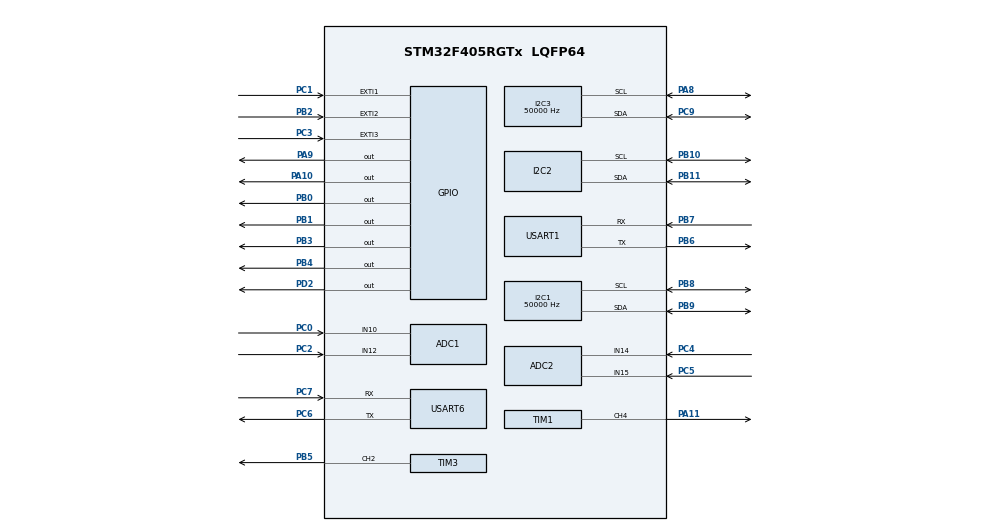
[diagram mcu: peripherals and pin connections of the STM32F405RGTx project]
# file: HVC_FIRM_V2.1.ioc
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ADC1.Channel-0\#ChannelRegularConversion=ADC_CHANNEL_10
ADC1.ClockPrescaler=ADC_CLOCK_SYNC_PCLK_DIV4
ADC1.NbrOfConversionFlag=1
ADC1.Rank-0\#ChannelRegularConversion=1
ADC1.SamplingTime-0\#ChannelRegularConversion=ADC_SAMPLETIME_3CYCLES
ADC1.master=1
ADC2.Channel-0\#ChannelRegularConversion=ADC_CHANNEL_14
ADC2.ClockPrescaler=ADC_CLOCK_SYNC_PCLK_DIV4
ADC2.NbrOfConversionFlag=1
ADC2.Rank-0\#ChannelRegularConversion=1
ADC2.SamplingTime-0\#ChannelRegularConversion=ADC_SAMPLETIME_3CYCLES
I2C1.ClockSpeed=50000
I2C3.ClockSpeed=50000
Mcu.Family=STM32F4
Mcu.Name=STM32F405RGTx
Mcu.Package=LQFP64
NVIC.ADC_IRQn=true\:3\:0\:true\:false\:true\:true\:true\:true
NVIC.EXTI1_IRQn=true\:1\:0\:true\:false\:true\:true\:true\:true
NVIC.EXTI2_IRQn=true\:2\:0\:true\:false\:true\:true\:true\:true
NVIC.EXTI3_IRQn=true\:1\:0\:true\:false\:true\:true\:true\:true
NVIC.PriorityGroup=NVIC_PRIORITYGROUP_4
NVIC.USART1_IRQn=true\:2\:0\:true\:false\:true\:true\:true\:true
NVIC.USART6_IRQn=true\:6\:0\:true\:false\:true\:true\:true\:true
PA10.Signal=GPIO_Output
PA11.Signal=S_TIM1_CH4
PA13.Mode=Serial_Wire
PA13.Signal=SYS_JTMS-SWDIO
PA14.Mode=Serial_Wire
PA14.Signal=SYS_JTCK-SWCLK
PA8.Mode=I2C
PA8.Signal=I2C3_SCL
PA9.Signal=GPIO_Output
PB0.Signal=GPIO_Output
PB1.Signal=GPIO_Output
PB10.Mode=I2C
PB10.Signal=I2C2_SCL
PB11.Mode=I2C
PB11.Signal=I2C2_SDA
PB2.GPIO_ModeDefaultEXTI=GPIO_MODE_IT_FALLING
PB2.Signal=GPXTI2
PB3.Signal=GPIO_Output
PB4.Signal=GPIO_Output
PB5.Signal=S_TIM3_CH2
PB6.Mode=Asynchronous
PB6.Signal=USART1_TX
PB7.GPIO_PuPd=GPIO_PULLUP
PB7.Mode=Asynchronous
PB7.Signal=USART1_RX
PB8.Mode=I2C
PB8.Signal=I2C1_SCL
PB9.Mode=I2C
PB9.Signal=I2C1_SDA
PC0.Signal=ADCx_IN10
PC1.Signal=GPXTI1
PC2.Signal=ADCx_IN12
PC3.Signal=GPXTI3
PC4.Signal=ADCx_IN14
PC5.Signal=ADCx_IN15
PC6.Mode=Asynchronous
PC6.Signal=USART6_TX
PC7.GPIO_PuPd=GPIO_PULLUP
PC7.Mode=Asynchronous
PC7.Signal=USART6_RX
PC9.Mode=I2C
PC9.Signal=I2C3_SDA
PD2.Signal=GPIO_Output
PH0-OSC_IN.Mode=HSE-External-Oscillator
PH0-OSC_IN.Signal=RCC_OSC_IN
PH1-OSC_OUT.Mode=HSE-External-Oscillator
PH1-OSC_OUT.Signal=RCC_OSC_OUT
ProjectManager.HeapSize=0x200
ProjectManager.StackSize=0x400
ProjectManager.TargetToolchain=STM32CubeIDE
RCC.48MHZClocksFreq_Value=36000000
RCC.AHBCLKDivider=RCC_SYSCLK_DIV2
RCC.AHBFreq_Value=36000000
RCC.APB1Freq_Value=36000000
RCC.APB1TimFreq_Value=36000000
RCC.APB2Freq_Value=36000000
RCC.APB2TimFreq_Value=36000000
RCC.CortexFreq_Value=36000000
RCC.HCLKFreq_Value=36000000
RCC.HSE_VALUE=8000000
RCC.HSI_VALUE=16000000
RCC.LSE_VALUE=32768
RCC.PLLM=4
RCC.PLLN=72
RCC.PLLSourceVirtual=RCC_PLLSOURCE_HSE
RCC.SYSCLKFreq_VALUE=72000000
RCC.SYSCLKSource=RCC_SYSCLKSOURCE_PLLCLK
RCC.VCOOutputFreq_Value=144000000
SH.ADCx_IN10.0=ADC1_IN10,IN10
SH.ADCx_IN12.0=ADC1_IN12,IN12
SH.ADCx_IN14.0=ADC2_IN14,IN14
SH.ADCx_IN15.0=ADC2_IN15,IN15
SH.S_TIM1_CH4.0=TIM1_CH4,PWM Generation4 CH4
SH.S_TIM3_CH2.0=TIM3_CH2,PWM Generation2 CH2
TIM1.Channel-PWM\ Generation4\ CH4=TIM_CHANNEL_4
TIM3.Channel-PWM\ Generation2\ CH2=TIM_CHANNEL_2
USART1.VirtualMode=VM_ASYNC
USART6.VirtualMode=VM_ASYNC
board=custom

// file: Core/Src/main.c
/* USER CODE BEGIN Header */
/**
  ******************************************************************************
  * @file           : main.c
  * @brief          : Main program body
  ******************************************************************************
  * @attention
  *
  * Copyright (c) 2026 STMicroelectronics.
  * All rights reserved.
  *
  * This software is licensed under terms that can be found in the LICENSE file
  * in the root directory of this software component.
  * If no LICENSE file comes with this software, it is provided AS-IS.
  *
  ******************************************************************************
  */
/* USER CODE END Header */
#include "main.h"

/* USER CODE BEGIN Includes */
#include "app.h"

/* USER CODE END Includes */

void SystemClock_Config(void);
static void MX_GPIO_Init(void);
static void MX_ADC1_Init(void);
static void MX_TIM1_Init(void);
static void MX_TIM3_Init(void);
static void MX_USART6_UART_Init(void);
static void MX_USART1_UART_Init(void);
static void MX_I2C1_Init(void);
static void MX_I2C3_Init(void);
static void MX_ADC2_Init(void);
static void MX_I2C2_Init(void);

/* USER CODE BEGIN 0 */
void I2C1_Init_Bridge(void){
	MX_I2C1_Init();
}
void I2C2_Init_Bridge(void){
	MX_I2C2_Init();
}
void I2C3_Init_Bridge(void){
	MX_I2C3_Init();
}

/* USER CODE END 0 */

int main(void)
{

  /* MCU Configuration--------------------------------------------------------*/

  /* Reset of all peripherals, Initializes the Flash interface and the Systick. */
  LL_APB2_GRP1_EnableClock(LL_APB2_GRP1_PERIPH_SYSCFG);
  LL_APB1_GRP1_EnableClock(LL_APB1_GRP1_PERIPH_PWR);

  /* System interrupt init*/
  NVIC_SetPriorityGrouping(NVIC_PRIORITYGROUP_4);

  /* SysTick_IRQn interrupt configuration */
  NVIC_SetPriority(SysTick_IRQn, NVIC_EncodePriority(NVIC_GetPriorityGrouping(),15, 0));

  /* Configure the system clock */
  SystemClock_Config();

  /* Initialize all configured peripherals */
  MX_GPIO_Init();
  MX_ADC1_Init();
  MX_TIM1_Init();
  MX_TIM3_Init();
  MX_USART6_UART_Init();
  MX_USART1_UART_Init();
  MX_I2C1_Init();
  MX_I2C3_Init();
  MX_ADC2_Init();
  MX_I2C2_Init();
  /* USER CODE BEGIN 2 */

  App_Main();

  /* USER CODE END 2 */

  /* Infinite loop */
  while (1)
  {

  }
}

void SystemClock_Config(void)
{
  LL_FLASH_SetLatency(LL_FLASH_LATENCY_1);
  while(LL_FLASH_GetLatency()!= LL_FLASH_LATENCY_1)
  {
  }
  LL_PWR_SetRegulVoltageScaling(LL_PWR_REGU_VOLTAGE_SCALE1);
  LL_RCC_HSE_Enable();

   /* Wait till HSE is ready */
  while(LL_RCC_HSE_IsReady() != 1)
  {

  }
  LL_RCC_PLL_ConfigDomain_SYS(LL_RCC_PLLSOURCE_HSE, LL_RCC_PLLM_DIV_4, 72, LL_RCC_PLLP_DIV_2);
  LL_RCC_PLL_Enable();

   /* Wait till PLL is ready */
  while(LL_RCC_PLL_IsReady() != 1)
  {

  }
  while (LL_PWR_IsActiveFlag_VOS() == 0)
  {
  }
  LL_RCC_SetAHBPrescaler(LL_RCC_SYSCLK_DIV_2);
  LL_RCC_SetAPB1Prescaler(LL_RCC_APB1_DIV_1);
  LL_RCC_SetAPB2Prescaler(LL_RCC_APB2_DIV_1);
  LL_RCC_SetSysClkSource(LL_RCC_SYS_CLKSOURCE_PLL);

   /* Wait till System clock is ready */
  while(LL_RCC_GetSysClkSource() != LL_RCC_SYS_CLKSOURCE_STATUS_PLL)
  {

  }
  LL_Init1msTick(36000000);
  LL_SetSystemCoreClock(36000000);
}

static void MX_ADC1_Init(void)
{

  LL_ADC_InitTypeDef ADC_InitStruct = {0};
  LL_ADC_REG_InitTypeDef ADC_REG_InitStruct = {0};
  LL_ADC_CommonInitTypeDef ADC_CommonInitStruct = {0};

  LL_GPIO_InitTypeDef GPIO_InitStruct = {0};

  /* Peripheral clock enable */
  LL_APB2_GRP1_EnableClock(LL_APB2_GRP1_PERIPH_ADC1);

  LL_AHB1_GRP1_EnableClock(LL_AHB1_GRP1_PERIPH_GPIOC);
  /**ADC1 GPIO Configuration
  PC0   ------> ADC1_IN10
  PC2   ------> ADC1_IN12
  */
  GPIO_InitStruct.Pin = LL_GPIO_PIN_0|LL_GPIO_PIN_2;
  GPIO_InitStruct.Mode = LL_GPIO_MODE_ANALOG;
  GPIO_InitStruct.Pull = LL_GPIO_PULL_NO;
  LL_GPIO_Init(GPIOC, &GPIO_InitStruct);

  /* ADC1 interrupt Init */
  NVIC_SetPriority(ADC_IRQn, NVIC_EncodePriority(NVIC_GetPriorityGrouping(),3, 0));
  NVIC_EnableIRQ(ADC_IRQn);

  /** Common config
  */
  ADC_InitStruct.Resolution = LL_ADC_RESOLUTION_12B;
  ADC_InitStruct.DataAlignment = LL_ADC_DATA_ALIGN_RIGHT;
  ADC_InitStruct.SequencersScanMode = LL_ADC_SEQ_SCAN_DISABLE;
  LL_ADC_Init(ADC1, &ADC_InitStruct);
  ADC_REG_InitStruct.TriggerSource = LL_ADC_REG_TRIG_SOFTWARE;
  ADC_REG_InitStruct.SequencerLength = LL_ADC_REG_SEQ_SCAN_DISABLE;
  ADC_REG_InitStruct.SequencerDiscont = LL_ADC_REG_SEQ_DISCONT_DISABLE;
  ADC_REG_InitStruct.ContinuousMode = LL_ADC_REG_CONV_SINGLE;
  ADC_REG_InitStruct.DMATransfer = LL_ADC_REG_DMA_TRANSFER_NONE;
  LL_ADC_REG_Init(ADC1, &ADC_REG_InitStruct);
  LL_ADC_REG_SetFlagEndOfConversion(ADC1, LL_ADC_REG_FLAG_EOC_UNITARY_CONV);
  ADC_CommonInitStruct.CommonClock = LL_ADC_CLOCK_SYNC_PCLK_DIV4;
  ADC_CommonInitStruct.Multimode = LL_ADC_MULTI_INDEPENDENT;
  LL_ADC_CommonInit(__LL_ADC_COMMON_INSTANCE(ADC1), &ADC_CommonInitStruct);

  /** Configure Regular Channel
  */
  LL_ADC_REG_SetSequencerRanks(ADC1, LL_ADC_REG_RANK_1, LL_ADC_CHANNEL_10);
  LL_ADC_SetChannelSamplingTime(ADC1, LL_ADC_CHANNEL_10, LL_ADC_SAMPLINGTIME_3CYCLES);

}

static void MX_ADC2_Init(void)
{

  LL_ADC_InitTypeDef ADC_InitStruct = {0};
  LL_ADC_REG_InitTypeDef ADC_REG_InitStruct = {0};

  LL_GPIO_InitTypeDef GPIO_InitStruct = {0};

  /* Peripheral clock enable */
  LL_APB2_GRP1_EnableClock(LL_APB2_GRP1_PERIPH_ADC2);

  LL_AHB1_GRP1_EnableClock(LL_AHB1_GRP1_PERIPH_GPIOC);
  /**ADC2 GPIO Configuration
  PC4   ------> ADC2_IN14
  PC5   ------> ADC2_IN15
  */
  GPIO_InitStruct.Pin = LL_GPIO_PIN_4|LL_GPIO_PIN_5;
  GPIO_InitStruct.Mode = LL_GPIO_MODE_ANALOG;
  GPIO_InitStruct.Pull = LL_GPIO_PULL_NO;
  LL_GPIO_Init(GPIOC, &GPIO_InitStruct);

  /* ADC2 interrupt Init */
  NVIC_SetPriority(ADC_IRQn, NVIC_EncodePriority(NVIC_GetPriorityGrouping(),3, 0));
  NVIC_EnableIRQ(ADC_IRQn);

  /** Common config
  */
  ADC_InitStruct.Resolution = LL_ADC_RESOLUTION_12B;
  ADC_InitStruct.DataAlignment = LL_ADC_DATA_ALIGN_RIGHT;
  ADC_InitStruct.SequencersScanMode = LL_ADC_SEQ_SCAN_DISABLE;
  LL_ADC_Init(ADC2, &ADC_InitStruct);
  ADC_REG_InitStruct.TriggerSource = LL_ADC_REG_TRIG_SOFTWARE;
  ADC_REG_InitStruct.SequencerLength = LL_ADC_REG_SEQ_SCAN_DISABLE;
  ADC_REG_InitStruct.SequencerDiscont = LL_ADC_REG_SEQ_DISCONT_DISABLE;
  ADC_REG_InitStruct.ContinuousMode = LL_ADC_REG_CONV_SINGLE;
  ADC_REG_InitStruct.DMATransfer = LL_ADC_REG_DMA_TRANSFER_NONE;
  LL_ADC_REG_Init(ADC2, &ADC_REG_InitStruct);
  LL_ADC_REG_SetFlagEndOfConversion(ADC2, LL_ADC_REG_FLAG_EOC_UNITARY_CONV);

  /** Configure Regular Channel
  */
  LL_ADC_REG_SetSequencerRanks(ADC2, LL_ADC_REG_RANK_1, LL_ADC_CHANNEL_14);
  LL_ADC_SetChannelSamplingTime(ADC2, LL_ADC_CHANNEL_14, LL_ADC_SAMPLINGTIME_3CYCLES);

}

static void MX_I2C1_Init(void)
{

  LL_I2C_InitTypeDef I2C_InitStruct = {0};

  LL_GPIO_InitTypeDef GPIO_InitStruct = {0};

  LL_AHB1_GRP1_EnableClock(LL_AHB1_GRP1_PERIPH_GPIOB);
  /**I2C1 GPIO Configuration
  PB8   ------> I2C1_SCL
  PB9   ------> I2C1_SDA
  */
  GPIO_InitStruct.Pin = LL_GPIO_PIN_8|LL_GPIO_PIN_9;
  GPIO_InitStruct.Mode = LL_GPIO_MODE_ALTERNATE;
  GPIO_InitStruct.Speed = LL_GPIO_SPEED_FREQ_VERY_HIGH;
  GPIO_InitStruct.OutputType = LL_GPIO_OUTPUT_OPENDRAIN;
  GPIO_InitStruct.Pull = LL_GPIO_PULL_NO;
  GPIO_InitStruct.Alternate = LL_GPIO_AF_4;
  LL_GPIO_Init(GPIOB, &GPIO_InitStruct);

  /* Peripheral clock enable */
  LL_APB1_GRP1_EnableClock(LL_APB1_GRP1_PERIPH_I2C1);

  /** I2C Initialization
  */
  LL_I2C_DisableOwnAddress2(I2C1);
  LL_I2C_DisableGeneralCall(I2C1);
  LL_I2C_EnableClockStretching(I2C1);
  I2C_InitStruct.PeripheralMode = LL_I2C_MODE_I2C;
  I2C_InitStruct.ClockSpeed = 50000;
  I2C_InitStruct.DutyCycle = LL_I2C_DUTYCYCLE_2;
  I2C_InitStruct.OwnAddress1 = 0;
  I2C_InitStruct.TypeAcknowledge = LL_I2C_ACK;
  I2C_InitStruct.OwnAddrSize = LL_I2C_OWNADDRESS1_7BIT;
  LL_I2C_Init(I2C1, &I2C_InitStruct);
  LL_I2C_SetOwnAddress2(I2C1, 0);

}

static void MX_I2C2_Init(void)
{

  LL_I2C_InitTypeDef I2C_InitStruct = {0};

  LL_GPIO_InitTypeDef GPIO_InitStruct = {0};

  LL_AHB1_GRP1_EnableClock(LL_AHB1_GRP1_PERIPH_GPIOB);
  /**I2C2 GPIO Configuration
  PB10   ------> I2C2_SCL
  PB11   ------> I2C2_SDA
  */
  GPIO_InitStruct.Pin = LL_GPIO_PIN_10|LL_GPIO_PIN_11;
  GPIO_InitStruct.Mode = LL_GPIO_MODE_ALTERNATE;
  GPIO_InitStruct.Speed = LL_GPIO_SPEED_FREQ_VERY_HIGH;
  GPIO_InitStruct.OutputType = LL_GPIO_OUTPUT_OPENDRAIN;
  GPIO_InitStruct.Pull = LL_GPIO_PULL_NO;
  GPIO_InitStruct.Alternate = LL_GPIO_AF_4;
  LL_GPIO_Init(GPIOB, &GPIO_InitStruct);

  /* Peripheral clock enable */
  LL_APB1_GRP1_EnableClock(LL_APB1_GRP1_PERIPH_I2C2);

  /** I2C Initialization
  */
  LL_I2C_DisableOwnAddress2(I2C2);
  LL_I2C_DisableGeneralCall(I2C2);
  LL_I2C_EnableClockStretching(I2C2);
  I2C_InitStruct.PeripheralMode = LL_I2C_MODE_I2C;
  I2C_InitStruct.ClockSpeed = 100000;
  I2C_InitStruct.DutyCycle = LL_I2C_DUTYCYCLE_2;
  I2C_InitStruct.OwnAddress1 = 0;
  I2C_InitStruct.TypeAcknowledge = LL_I2C_ACK;
  I2C_InitStruct.OwnAddrSize = LL_I2C_OWNADDRESS1_7BIT;
  LL_I2C_Init(I2C2, &I2C_InitStruct);
  LL_I2C_SetOwnAddress2(I2C2, 0);

}

static void MX_I2C3_Init(void)
{

  LL_I2C_InitTypeDef I2C_InitStruct = {0};

  LL_GPIO_InitTypeDef GPIO_InitStruct = {0};

  LL_AHB1_GRP1_EnableClock(LL_AHB1_GRP1_PERIPH_GPIOC);
  LL_AHB1_GRP1_EnableClock(LL_AHB1_GRP1_PERIPH_GPIOA);
  /**I2C3 GPIO Configuration
  PC9   ------> I2C3_SDA
  PA8   ------> I2C3_SCL
  */
  GPIO_InitStruct.Pin = LL_GPIO_PIN_9;
  GPIO_InitStruct.Mode = LL_GPIO_MODE_ALTERNATE;
  GPIO_InitStruct.Speed = LL_GPIO_SPEED_FREQ_VERY_HIGH;
  GPIO_InitStruct.OutputType = LL_GPIO_OUTPUT_OPENDRAIN;
  GPIO_InitStruct.Pull = LL_GPIO_PULL_NO;
  GPIO_InitStruct.Alternate = LL_GPIO_AF_4;
  LL_GPIO_Init(GPIOC, &GPIO_InitStruct);

  GPIO_InitStruct.Pin = LL_GPIO_PIN_8;
  GPIO_InitStruct.Mode = LL_GPIO_MODE_ALTERNATE;
  GPIO_InitStruct.Speed = LL_GPIO_SPEED_FREQ_VERY_HIGH;
  GPIO_InitStruct.OutputType = LL_GPIO_OUTPUT_OPENDRAIN;
  GPIO_InitStruct.Pull = LL_GPIO_PULL_NO;
  GPIO_InitStruct.Alternate = LL_GPIO_AF_4;
  LL_GPIO_Init(GPIOA, &GPIO_InitStruct);

  /* Peripheral clock enable */
  LL_APB1_GRP1_EnableClock(LL_APB1_GRP1_PERIPH_I2C3);

  /** I2C Initialization
  */
  LL_I2C_DisableOwnAddress2(I2C3);
  LL_I2C_DisableGeneralCall(I2C3);
  LL_I2C_EnableClockStretching(I2C3);
  I2C_InitStruct.PeripheralMode = LL_I2C_MODE_I2C;
  I2C_InitStruct.ClockSpeed = 50000;
  I2C_InitStruct.DutyCycle = LL_I2C_DUTYCYCLE_2;
  I2C_InitStruct.OwnAddress1 = 0;
  I2C_InitStruct.TypeAcknowledge = LL_I2C_ACK;
  I2C_InitStruct.OwnAddrSize = LL_I2C_OWNADDRESS1_7BIT;
  LL_I2C_Init(I2C3, &I2C_InitStruct);
  LL_I2C_SetOwnAddress2(I2C3, 0);

}

static void MX_TIM1_Init(void)
{

  LL_TIM_InitTypeDef TIM_InitStruct = {0};
  LL_TIM_OC_InitTypeDef TIM_OC_InitStruct = {0};
  LL_TIM_BDTR_InitTypeDef TIM_BDTRInitStruct = {0};

  LL_GPIO_InitTypeDef GPIO_InitStruct = {0};

  /* Peripheral clock enable */
  LL_APB2_GRP1_EnableClock(LL_APB2_GRP1_PERIPH_TIM1);

  TIM_InitStruct.Prescaler = 0;
  TIM_InitStruct.CounterMode = LL_TIM_COUNTERMODE_UP;
  TIM_InitStruct.Autoreload = 65535;
  TIM_InitStruct.ClockDivision = LL_TIM_CLOCKDIVISION_DIV1;
  TIM_InitStruct.RepetitionCounter = 0;
  LL_TIM_Init(TIM1, &TIM_InitStruct);
  LL_TIM_DisableARRPreload(TIM1);
  LL_TIM_OC_EnablePreload(TIM1, LL_TIM_CHANNEL_CH4);
  TIM_OC_InitStruct.OCMode = LL_TIM_OCMODE_PWM1;
  TIM_OC_InitStruct.OCState = LL_TIM_OCSTATE_DISABLE;
  TIM_OC_InitStruct.OCNState = LL_TIM_OCSTATE_DISABLE;
  TIM_OC_InitStruct.CompareValue = 0;
  TIM_OC_InitStruct.OCPolarity = LL_TIM_OCPOLARITY_HIGH;
  TIM_OC_InitStruct.OCIdleState = LL_TIM_OCIDLESTATE_LOW;
  TIM_OC_InitStruct.OCNIdleState = LL_TIM_OCIDLESTATE_LOW;
  LL_TIM_OC_Init(TIM1, LL_TIM_CHANNEL_CH4, &TIM_OC_InitStruct);
  LL_TIM_OC_DisableFast(TIM1, LL_TIM_CHANNEL_CH4);
  LL_TIM_SetTriggerOutput(TIM1, LL_TIM_TRGO_RESET);
  LL_TIM_DisableMasterSlaveMode(TIM1);
  TIM_BDTRInitStruct.OSSRState = LL_TIM_OSSR_DISABLE;
  TIM_BDTRInitStruct.OSSIState = LL_TIM_OSSI_DISABLE;
  TIM_BDTRInitStruct.LockLevel = LL_TIM_LOCKLEVEL_OFF;
  TIM_BDTRInitStruct.DeadTime = 0;
  TIM_BDTRInitStruct.BreakState = LL_TIM_BREAK_DISABLE;
  TIM_BDTRInitStruct.BreakPolarity = LL_TIM_BREAK_POLARITY_HIGH;
  TIM_BDTRInitStruct.AutomaticOutput = LL_TIM_AUTOMATICOUTPUT_DISABLE;
  LL_TIM_BDTR_Init(TIM1, &TIM_BDTRInitStruct);
  LL_AHB1_GRP1_EnableClock(LL_AHB1_GRP1_PERIPH_GPIOA);
  /**TIM1 GPIO Configuration
  PA11   ------> TIM1_CH4
  */
  GPIO_InitStruct.Pin = LL_GPIO_PIN_11;
  GPIO_InitStruct.Mode = LL_GPIO_MODE_ALTERNATE;
  GPIO_InitStruct.Speed = LL_GPIO_SPEED_FREQ_LOW;
  GPIO_InitStruct.OutputType = LL_GPIO_OUTPUT_PUSHPULL;
  GPIO_InitStruct.Pull = LL_GPIO_PULL_NO;
  GPIO_InitStruct.Alternate = LL_GPIO_AF_1;
  LL_GPIO_Init(GPIOA, &GPIO_InitStruct);

}

static void MX_TIM3_Init(void)
{

  LL_TIM_InitTypeDef TIM_InitStruct = {0};
  LL_TIM_OC_InitTypeDef TIM_OC_InitStruct = {0};

  LL_GPIO_InitTypeDef GPIO_InitStruct = {0};

  /* Peripheral clock enable */
  LL_APB1_GRP1_EnableClock(LL_APB1_GRP1_PERIPH_TIM3);

  TIM_InitStruct.Prescaler = 0;
  TIM_InitStruct.CounterMode = LL_TIM_COUNTERMODE_UP;
  TIM_InitStruct.Autoreload = 65535;
  TIM_InitStruct.ClockDivision = LL_TIM_CLOCKDIVISION_DIV1;
  LL_TIM_Init(TIM3, &TIM_InitStruct);
  LL_TIM_DisableARRPreload(TIM3);
  LL_TIM_OC_EnablePreload(TIM3, LL_TIM_CHANNEL_CH2);
  TIM_OC_InitStruct.OCMode = LL_TIM_OCMODE_PWM1;
  TIM_OC_InitStruct.OCState = LL_TIM_OCSTATE_DISABLE;
  TIM_OC_InitStruct.OCNState = LL_TIM_OCSTATE_DISABLE;
  TIM_OC_InitStruct.CompareValue = 0;
  TIM_OC_InitStruct.OCPolarity = LL_TIM_OCPOLARITY_HIGH;
  LL_TIM_OC_Init(TIM3, LL_TIM_CHANNEL_CH2, &TIM_OC_InitStruct);
  LL_TIM_OC_DisableFast(TIM3, LL_TIM_CHANNEL_CH2);
  LL_TIM_SetTriggerOutput(TIM3, LL_TIM_TRGO_RESET);
  LL_TIM_DisableMasterSlaveMode(TIM3);
  LL_AHB1_GRP1_EnableClock(LL_AHB1_GRP1_PERIPH_GPIOB);
  /**TIM3 GPIO Configuration
  PB5   ------> TIM3_CH2
  */
  GPIO_InitStruct.Pin = LL_GPIO_PIN_5;
  GPIO_InitStruct.Mode = LL_GPIO_MODE_ALTERNATE;
  GPIO_InitStruct.Speed = LL_GPIO_SPEED_FREQ_LOW;
  GPIO_InitStruct.OutputType = LL_GPIO_OUTPUT_PUSHPULL;
  GPIO_InitStruct.Pull = LL_GPIO_PULL_NO;
  GPIO_InitStruct.Alternate = LL_GPIO_AF_2;
  LL_GPIO_Init(GPIOB, &GPIO_InitStruct);

}

static void MX_USART1_UART_Init(void)
{

  LL_USART_InitTypeDef USART_InitStruct = {0};

  LL_GPIO_InitTypeDef GPIO_InitStruct = {0};

  /* Peripheral clock enable */
  LL_APB2_GRP1_EnableClock(LL_APB2_GRP1_PERIPH_USART1);

  LL_AHB1_GRP1_EnableClock(LL_AHB1_GRP1_PERIPH_GPIOB);
  /**USART1 GPIO Configuration
  PB6   ------> USART1_TX
  PB7   ------> USART1_RX
  */
  GPIO_InitStruct.Pin = LL_GPIO_PIN_6;
  GPIO_InitStruct.Mode = LL_GPIO_MODE_ALTERNATE;
  GPIO_InitStruct.Speed = LL_GPIO_SPEED_FREQ_VERY_HIGH;
  GPIO_InitStruct.OutputType = LL_GPIO_OUTPUT_PUSHPULL;
  GPIO_InitStruct.Pull = LL_GPIO_PULL_NO;
  GPIO_InitStruct.Alternate = LL_GPIO_AF_7;
  LL_GPIO_Init(GPIOB, &GPIO_InitStruct);

  GPIO_InitStruct.Pin = LL_GPIO_PIN_7;
  GPIO_InitStruct.Mode = LL_GPIO_MODE_ALTERNATE;
  GPIO_InitStruct.Speed = LL_GPIO_SPEED_FREQ_VERY_HIGH;
  GPIO_InitStruct.OutputType = LL_GPIO_OUTPUT_PUSHPULL;
  GPIO_InitStruct.Pull = LL_GPIO_PULL_UP;
  GPIO_InitStruct.Alternate = LL_GPIO_AF_7;
  LL_GPIO_Init(GPIOB, &GPIO_InitStruct);

  /* USART1 interrupt Init */
  NVIC_SetPriority(USART1_IRQn, NVIC_EncodePriority(NVIC_GetPriorityGrouping(),2, 0));
  NVIC_EnableIRQ(USART1_IRQn);

  USART_InitStruct.BaudRate = 115200;
  USART_InitStruct.DataWidth = LL_USART_DATAWIDTH_8B;
  USART_InitStruct.StopBits = LL_USART_STOPBITS_1;
  USART_InitStruct.Parity = LL_USART_PARITY_NONE;
  USART_InitStruct.TransferDirection = LL_USART_DIRECTION_TX_RX;
  USART_InitStruct.HardwareFlowControl = LL_USART_HWCONTROL_NONE;
  USART_InitStruct.OverSampling = LL_USART_OVERSAMPLING_16;
  LL_USART_Init(USART1, &USART_InitStruct);
  LL_USART_ConfigAsyncMode(USART1);
  LL_USART_Enable(USART1);

}

static void MX_USART6_UART_Init(void)
{

  LL_USART_InitTypeDef USART_InitStruct = {0};

  LL_GPIO_InitTypeDef GPIO_InitStruct = {0};

  /* Peripheral clock enable */
  LL_APB2_GRP1_EnableClock(LL_APB2_GRP1_PERIPH_USART6);

  LL_AHB1_GRP1_EnableClock(LL_AHB1_GRP1_PERIPH_GPIOC);
  /**USART6 GPIO Configuration
  PC6   ------> USART6_TX
  PC7   ------> USART6_RX
  */
  GPIO_InitStruct.Pin = LL_GPIO_PIN_6;
  GPIO_InitStruct.Mode = LL_GPIO_MODE_ALTERNATE;
  GPIO_InitStruct.Speed = LL_GPIO_SPEED_FREQ_VERY_HIGH;
  GPIO_InitStruct.OutputType = LL_GPIO_OUTPUT_PUSHPULL;
  GPIO_InitStruct.Pull = LL_GPIO_PULL_NO;
  GPIO_InitStruct.Alternate = LL_GPIO_AF_8;
  LL_GPIO_Init(GPIOC, &GPIO_InitStruct);

  GPIO_InitStruct.Pin = LL_GPIO_PIN_7;
  GPIO_InitStruct.Mode = LL_GPIO_MODE_ALTERNATE;
  GPIO_InitStruct.Speed = LL_GPIO_SPEED_FREQ_VERY_HIGH;
  GPIO_InitStruct.OutputType = LL_GPIO_OUTPUT_PUSHPULL;
  GPIO_InitStruct.Pull = LL_GPIO_PULL_UP;
  GPIO_InitStruct.Alternate = LL_GPIO_AF_8;
  LL_GPIO_Init(GPIOC, &GPIO_InitStruct);

  /* USART6 interrupt Init */
  NVIC_SetPriority(USART6_IRQn, NVIC_EncodePriority(NVIC_GetPriorityGrouping(),6, 0));
  NVIC_EnableIRQ(USART6_IRQn);

  USART_InitStruct.BaudRate = 115200;
  USART_InitStruct.DataWidth = LL_USART_DATAWIDTH_8B;
  USART_InitStruct.StopBits = LL_USART_STOPBITS_1;
  USART_InitStruct.Parity = LL_USART_PARITY_NONE;
  USART_InitStruct.TransferDirection = LL_USART_DIRECTION_TX_RX;
  USART_InitStruct.HardwareFlowControl = LL_USART_HWCONTROL_NONE;
  USART_InitStruct.OverSampling = LL_USART_OVERSAMPLING_16;
  LL_USART_Init(USART6, &USART_InitStruct);
  LL_USART_ConfigAsyncMode(USART6);
  LL_USART_Enable(USART6);

}

static void MX_GPIO_Init(void)
{
  LL_EXTI_InitTypeDef EXTI_InitStruct = {0};
  LL_GPIO_InitTypeDef GPIO_InitStruct = {0};

  /* GPIO Ports Clock Enable */
  LL_AHB1_GRP1_EnableClock(LL_AHB1_GRP1_PERIPH_GPIOH);
  LL_AHB1_GRP1_EnableClock(LL_AHB1_GRP1_PERIPH_GPIOC);
  LL_AHB1_GRP1_EnableClock(LL_AHB1_GRP1_PERIPH_GPIOB);
  LL_AHB1_GRP1_EnableClock(LL_AHB1_GRP1_PERIPH_GPIOA);
  LL_AHB1_GRP1_EnableClock(LL_AHB1_GRP1_PERIPH_GPIOD);

  /**/
  LL_GPIO_ResetOutputPin(GPIOB, LL_GPIO_PIN_0|LL_GPIO_PIN_1|LL_GPIO_PIN_3|LL_GPIO_PIN_4);

  /**/
  LL_GPIO_ResetOutputPin(GPIOA, LL_GPIO_PIN_9|LL_GPIO_PIN_10);

  /**/
  LL_GPIO_ResetOutputPin(GPIOD, LL_GPIO_PIN_2);

  /**/
  LL_SYSCFG_SetEXTISource(LL_SYSCFG_EXTI_PORTC, LL_SYSCFG_EXTI_LINE1);

  /**/
  LL_SYSCFG_SetEXTISource(LL_SYSCFG_EXTI_PORTC, LL_SYSCFG_EXTI_LINE3);

  /**/
  LL_SYSCFG_SetEXTISource(LL_SYSCFG_EXTI_PORTB, LL_SYSCFG_EXTI_LINE2);

  /**/
  EXTI_InitStruct.Line_0_31 = LL_EXTI_LINE_1;
  EXTI_InitStruct.LineCommand = ENABLE;
  EXTI_InitStruct.Mode = LL_EXTI_MODE_IT;
  EXTI_InitStruct.Trigger = LL_EXTI_TRIGGER_RISING;
  LL_EXTI_Init(&EXTI_InitStruct);

  /**/
  EXTI_InitStruct.Line_0_31 = LL_EXTI_LINE_3;
  EXTI_InitStruct.LineCommand = ENABLE;
  EXTI_InitStruct.Mode = LL_EXTI_MODE_IT;
  EXTI_InitStruct.Trigger = LL_EXTI_TRIGGER_RISING;
  LL_EXTI_Init(&EXTI_InitStruct);

  /**/
  EXTI_InitStruct.Line_0_31 = LL_EXTI_LINE_2;
  EXTI_InitStruct.LineCommand = ENABLE;
  EXTI_InitStruct.Mode = LL_EXTI_MODE_IT;
  EXTI_InitStruct.Trigger = LL_EXTI_TRIGGER_FALLING;
  LL_EXTI_Init(&EXTI_InitStruct);

  /**/
  LL_GPIO_SetPinPull(GPIOC, LL_GPIO_PIN_1, LL_GPIO_PULL_NO);

  /**/
  LL_GPIO_SetPinPull(GPIOC, LL_GPIO_PIN_3, LL_GPIO_PULL_NO);

  /**/
  LL_GPIO_SetPinPull(GPIOB, LL_GPIO_PIN_2, LL_GPIO_PULL_NO);

  /**/
  LL_GPIO_SetPinMode(GPIOC, LL_GPIO_PIN_1, LL_GPIO_MODE_INPUT);

  /**/
  LL_GPIO_SetPinMode(GPIOC, LL_GPIO_PIN_3, LL_GPIO_MODE_INPUT);

  /**/
  LL_GPIO_SetPinMode(GPIOB, LL_GPIO_PIN_2, LL_GPIO_MODE_INPUT);

  /**/
  GPIO_InitStruct.Pin = LL_GPIO_PIN_0|LL_GPIO_PIN_1|LL_GPIO_PIN_3|LL_GPIO_PIN_4;
  GPIO_InitStruct.Mode = LL_GPIO_MODE_OUTPUT;
  GPIO_InitStruct.Speed = LL_GPIO_SPEED_FREQ_LOW;
  GPIO_InitStruct.OutputType = LL_GPIO_OUTPUT_PUSHPULL;
  GPIO_InitStruct.Pull = LL_GPIO_PULL_NO;
  LL_GPIO_Init(GPIOB, &GPIO_InitStruct);

  /**/
  GPIO_InitStruct.Pin = LL_GPIO_PIN_9|LL_GPIO_PIN_10;
  GPIO_InitStruct.Mode = LL_GPIO_MODE_OUTPUT;
  GPIO_InitStruct.Speed = LL_GPIO_SPEED_FREQ_LOW;
  GPIO_InitStruct.OutputType = LL_GPIO_OUTPUT_PUSHPULL;
  GPIO_InitStruct.Pull = LL_GPIO_PULL_NO;
  LL_GPIO_Init(GPIOA, &GPIO_InitStruct);

  /**/
  GPIO_InitStruct.Pin = LL_GPIO_PIN_2;
  GPIO_InitStruct.Mode = LL_GPIO_MODE_OUTPUT;
  GPIO_InitStruct.Speed = LL_GPIO_SPEED_FREQ_LOW;
  GPIO_InitStruct.OutputType = LL_GPIO_OUTPUT_PUSHPULL;
  GPIO_InitStruct.Pull = LL_GPIO_PULL_NO;
  LL_GPIO_Init(GPIOD, &GPIO_InitStruct);

  /* EXTI interrupt init*/
  NVIC_SetPriority(EXTI1_IRQn, NVIC_EncodePriority(NVIC_GetPriorityGrouping(),1, 0));
  NVIC_EnableIRQ(EXTI1_IRQn);
  NVIC_SetPriority(EXTI2_IRQn, NVIC_EncodePriority(NVIC_GetPriorityGrouping(),2, 0));
  NVIC_EnableIRQ(EXTI2_IRQn);
  NVIC_SetPriority(EXTI3_IRQn, NVIC_EncodePriority(NVIC_GetPriorityGrouping(),1, 0));
  NVIC_EnableIRQ(EXTI3_IRQn);

}

void Error_Handler(void)
{
  __disable_irq();
  while (1)
  {
  }
}
